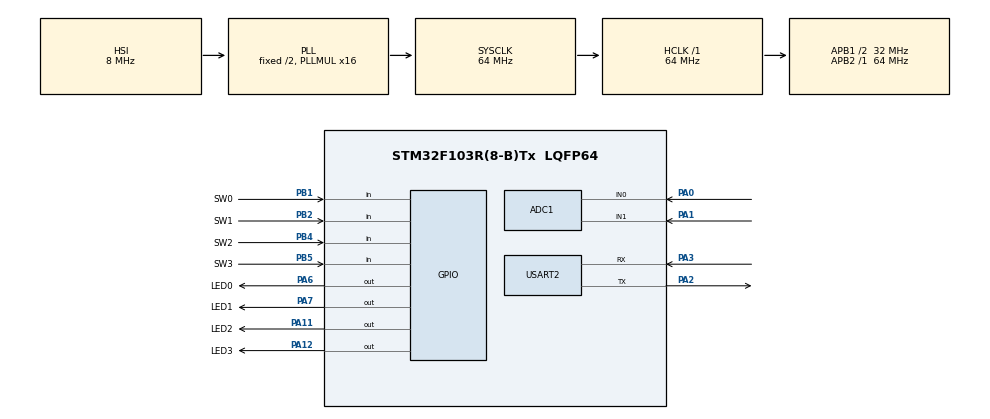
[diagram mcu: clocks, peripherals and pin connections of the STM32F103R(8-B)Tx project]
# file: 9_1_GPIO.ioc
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ADC1.Channel-0\#ChannelRegularConversion=ADC_CHANNEL_0
ADC1.Channel-1\#ChannelRegularConversion=ADC_CHANNEL_0
ADC1.ContinuousConvMode=ENABLE
ADC1.NbrOfConversion=2
ADC1.NbrOfConversionFlag=1
ADC1.Rank-0\#ChannelRegularConversion=1
ADC1.Rank-1\#ChannelRegularConversion=2
ADC1.SamplingTime-0\#ChannelRegularConversion=ADC_SAMPLETIME_13CYCLES_5
ADC1.SamplingTime-1\#ChannelRegularConversion=ADC_SAMPLETIME_13CYCLES_5
ADC1.master=1
Mcu.Family=STM32F1
Mcu.Name=STM32F103R(8-B)Tx
Mcu.Package=LQFP64
NVIC.PriorityGroup=NVIC_PRIORITYGROUP_4
PA0-WKUP.Signal=ADCx_IN0
PA1.Signal=ADCx_IN1
PA11.GPIO_Label=LED2
PA11.PinState=GPIO_PIN_SET
PA11.Signal=GPIO_Output
PA12.GPIO_Label=LED3
PA12.PinState=GPIO_PIN_SET
PA12.Signal=GPIO_Output
PA13.Mode=Serial_Wire
PA13.Signal=SYS_JTMS-SWDIO
PA14.Mode=Serial_Wire
PA14.Signal=SYS_JTCK-SWCLK
PA2.Mode=Asynchronous
PA2.Signal=USART2_TX
PA3.Mode=Asynchronous
PA3.Signal=USART2_RX
PA6.GPIO_Label=LED0
PA6.PinState=GPIO_PIN_SET
PA6.Signal=GPIO_Output
PA7.GPIO_Label=LED1
PA7.PinState=GPIO_PIN_SET
PA7.Signal=GPIO_Output
PB1.GPIO_Label=SW0
PB1.Signal=GPIO_Input
PB2.GPIO_Label=SW1
PB2.Signal=GPIO_Input
PB4.GPIO_Label=SW2
PB4.Signal=GPIO_Input
PB5.GPIO_Label=SW3
PB5.Signal=GPIO_Input
ProjectManager.HeapSize=0x200
ProjectManager.StackSize=0x400
ProjectManager.TargetToolchain=STM32CubeIDE
RCC.ADCPresc=RCC_ADCPCLK2_DIV8
RCC.AHBFreq_Value=64000000
RCC.APB1CLKDivider=RCC_HCLK_DIV2
RCC.APB1Freq_Value=32000000
RCC.APB1TimFreq_Value=64000000
RCC.APB2Freq_Value=64000000
RCC.APB2TimFreq_Value=64000000
RCC.HCLKFreq_Value=64000000
RCC.PLLMUL=RCC_PLL_MUL16
RCC.SYSCLKFreq_VALUE=64000000
RCC.SYSCLKSource=RCC_SYSCLKSOURCE_PLLCLK
RCC.USBFreq_Value=64000000
SH.ADCx_IN0.0=ADC1_IN0,IN0
SH.ADCx_IN1.0=ADC1_IN1,IN1
USART2.VirtualMode=VM_ASYNC
board=custom

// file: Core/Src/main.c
/* USER CODE BEGIN Header */
/**
  ******************************************************************************
  * @file           : main.c
  * @brief          : Main program body
  ******************************************************************************
  * @attention
  *
  * Copyright (c) 2024 STMicroelectronics.
  * All rights reserved.
  *
  * This software is licensed under terms that can be found in the LICENSE file
  * in the root directory of this software component.
  * If no LICENSE file comes with this software, it is provided AS-IS.
  *
  ******************************************************************************
  */
/* USER CODE END Header */
#include "main.h"

ADC_HandleTypeDef hadc1;

UART_HandleTypeDef huart2;

void SystemClock_Config(void);
static void MX_GPIO_Init(void);
static void MX_USART2_UART_Init(void);
static void MX_ADC1_Init(void);

int main(void)
{

  /* MCU Configuration--------------------------------------------------------*/

  /* Reset of all peripherals, Initializes the Flash interface and the Systick. */
  HAL_Init();

  /* Configure the system clock */
  SystemClock_Config();

  /* Initialize all configured peripherals */
  MX_GPIO_Init();
  MX_USART2_UART_Init();
  MX_ADC1_Init();

  /* Infinite loop */
  /* USER CODE BEGIN WHILE */
  while (1)
  {

//	  HAL_GPIO_WritePin (LED0_GPIO_Port, LED0_Pin, GPIO_PIN_SET);
//	  HAL_GPIO_WritePin (LED1_GPIO_Port, LED0_Pin, GPIO_PIN_SET);
//	  HAL_GPIO_WritePin (LED2_GPIO_Port, LED0_Pin, GPIO_PIN_SET);
//	  HAL_GPIO_WritePin (LED3_GPIO_Port, LED0_Pin, GPIO_PIN_SET);
    /* USER CODE END WHILE */

  }
}

void SystemClock_Config(void)
{
  RCC_OscInitTypeDef RCC_OscInitStruct = {0};
  RCC_ClkInitTypeDef RCC_ClkInitStruct = {0};
  RCC_PeriphCLKInitTypeDef PeriphClkInit = {0};

  /** Initializes the RCC Oscillators according to the specified parameters
  * in the RCC_OscInitTypeDef structure.
  */
  RCC_OscInitStruct.OscillatorType = RCC_OSCILLATORTYPE_HSI;
  RCC_OscInitStruct.HSIState = RCC_HSI_ON;
  RCC_OscInitStruct.HSICalibrationValue = RCC_HSICALIBRATION_DEFAULT;
  RCC_OscInitStruct.PLL.PLLState = RCC_PLL_ON;
  RCC_OscInitStruct.PLL.PLLSource = RCC_PLLSOURCE_HSI_DIV2;
  RCC_OscInitStruct.PLL.PLLMUL = RCC_PLL_MUL16;
  if (HAL_RCC_OscConfig(&RCC_OscInitStruct) != HAL_OK)
  {
    Error_Handler();
  }

  /** Initializes the CPU, AHB and APB buses clocks
  */
  RCC_ClkInitStruct.ClockType = RCC_CLOCKTYPE_HCLK|RCC_CLOCKTYPE_SYSCLK
                              |RCC_CLOCKTYPE_PCLK1|RCC_CLOCKTYPE_PCLK2;
  RCC_ClkInitStruct.SYSCLKSource = RCC_SYSCLKSOURCE_PLLCLK;
  RCC_ClkInitStruct.AHBCLKDivider = RCC_SYSCLK_DIV1;
  RCC_ClkInitStruct.APB1CLKDivider = RCC_HCLK_DIV2;
  RCC_ClkInitStruct.APB2CLKDivider = RCC_HCLK_DIV1;

  if (HAL_RCC_ClockConfig(&RCC_ClkInitStruct, FLASH_LATENCY_2) != HAL_OK)
  {
    Error_Handler();
  }
  PeriphClkInit.PeriphClockSelection = RCC_PERIPHCLK_ADC;
  PeriphClkInit.AdcClockSelection = RCC_ADCPCLK2_DIV8;
  if (HAL_RCCEx_PeriphCLKConfig(&PeriphClkInit) != HAL_OK)
  {
    Error_Handler();
  }
}

static void MX_ADC1_Init(void)
{

  ADC_ChannelConfTypeDef sConfig = {0};

  /** Common config
  */
  hadc1.Instance = ADC1;
  hadc1.Init.ScanConvMode = ADC_SCAN_ENABLE;
  hadc1.Init.ContinuousConvMode = ENABLE;
  hadc1.Init.DiscontinuousConvMode = DISABLE;
  hadc1.Init.ExternalTrigConv = ADC_SOFTWARE_START;
  hadc1.Init.DataAlign = ADC_DATAALIGN_RIGHT;
  hadc1.Init.NbrOfConversion = 2;
  if (HAL_ADC_Init(&hadc1) != HAL_OK)
  {
    Error_Handler();
  }

  /** Configure Regular Channel
  */
  sConfig.Channel = ADC_CHANNEL_0;
  sConfig.Rank = ADC_REGULAR_RANK_1;
  sConfig.SamplingTime = ADC_SAMPLETIME_13CYCLES_5;
  if (HAL_ADC_ConfigChannel(&hadc1, &sConfig) != HAL_OK)
  {
    Error_Handler();
  }

  /** Configure Regular Channel
  */
  sConfig.Rank = ADC_REGULAR_RANK_2;
  if (HAL_ADC_ConfigChannel(&hadc1, &sConfig) != HAL_OK)
  {
    Error_Handler();
  }

}

static void MX_USART2_UART_Init(void)
{

  huart2.Instance = USART2;
  huart2.Init.BaudRate = 115200;
  huart2.Init.WordLength = UART_WORDLENGTH_8B;
  huart2.Init.StopBits = UART_STOPBITS_1;
  huart2.Init.Parity = UART_PARITY_NONE;
  huart2.Init.Mode = UART_MODE_TX_RX;
  huart2.Init.HwFlowCtl = UART_HWCONTROL_NONE;
  huart2.Init.OverSampling = UART_OVERSAMPLING_16;
  if (HAL_UART_Init(&huart2) != HAL_OK)
  {
    Error_Handler();
  }

}

static void MX_GPIO_Init(void)
{
  GPIO_InitTypeDef GPIO_InitStruct = {0};

  /* GPIO Ports Clock Enable */
  __HAL_RCC_GPIOA_CLK_ENABLE();
  __HAL_RCC_GPIOB_CLK_ENABLE();

  /*Configure GPIO pin Output Level */
  HAL_GPIO_WritePin(GPIOA, LED0_Pin|LED1_Pin|LED2_Pin|LED3_Pin, GPIO_PIN_SET);

  /*Configure GPIO pins : LED0_Pin LED1_Pin LED2_Pin LED3_Pin */
  GPIO_InitStruct.Pin = LED0_Pin|LED1_Pin|LED2_Pin|LED3_Pin;
  GPIO_InitStruct.Mode = GPIO_MODE_OUTPUT_PP;
  GPIO_InitStruct.Pull = GPIO_NOPULL;
  GPIO_InitStruct.Speed = GPIO_SPEED_FREQ_LOW;
  HAL_GPIO_Init(GPIOA, &GPIO_InitStruct);

  /*Configure GPIO pins : SW0_Pin SW1_Pin SW2_Pin SW3_Pin */
  GPIO_InitStruct.Pin = SW0_Pin|SW1_Pin|SW2_Pin|SW3_Pin;
  GPIO_InitStruct.Mode = GPIO_MODE_INPUT;
  GPIO_InitStruct.Pull = GPIO_NOPULL;
  HAL_GPIO_Init(GPIOB, &GPIO_InitStruct);

}

void Error_Handler(void)
{
  __disable_irq();
  while (1)
  {
  }
}
